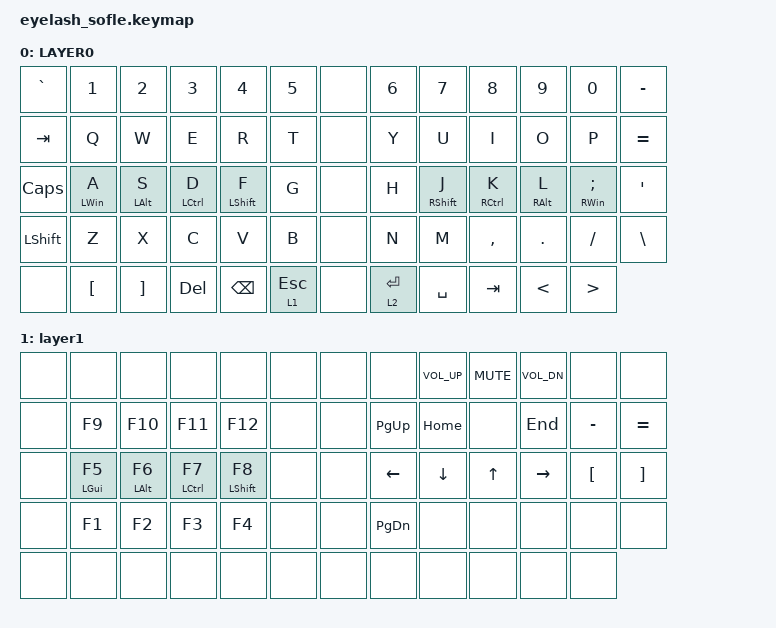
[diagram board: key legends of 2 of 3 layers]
#include <behaviors.dtsi>
#include <dt-bindings/zmk/keys.h>

/ {
    combos { compatible = "zmk,combos"; };

    keymap {
        compatible = "zmk,keymap";

        Base {
            bindings = <
&kp GRAVE  &kp N1            &kp N2             &kp N3       &kp N4         &kp N5       &none  &kp N6       &kp N7             &kp N8       &kp N9           &kp N0            &kp MINUS
&kp TAB    &kp Q             &kp W              &kp E        &kp R          &kp T        &none  &kp Y        &kp U              &kp I        &kp O            &kp P             &kp EQUAL
&kp CAPS   &mt LWIN A        &mt LEFT_ALT S     &mt LCTRL D  &mt LSHIFT F   &kp G        &none  &kp H        &mt RIGHT_SHIFT J  &mt RCTRL K  &mt RIGHT_ALT L  &mt RWIN SEMI     &kp APOS
&kp LSHFT  &kp Z             &kp X              &kp C        &kp V          &kp B        &none  &kp N        &kp M              &kp COMMA    &kp DOT          &kp FSLH          &kp BACKSLASH
&none      &kp LEFT_BRACKET  &kp RIGHT_BRACKET  &kp DEL      &kp BACKSPACE  &lt 1 ESC    &none  &lt 2 ENTER  &kp SPACE          &kp TAB      &kp LESS_THAN    &kp GREATER_THAN
            >;

            display-name = "LAYER0";
        };

        Funcs-Cursor {
            bindings = <
&none  &none            &none            &none                &none              &none    &none  &none           &kp C_VOL_UP    &kp K_MUTE    &kp C_VOL_DN  &none             &none
&none  &kp F9           &kp F10          &kp F11              &kp F12            &none    &none  &kp PG_UP       &kp HOME        &none         &kp END       &kp MINUS         &kp EQUAL
&none  &mt LEFT_GUI F5  &mt LEFT_ALT F6  &mt LEFT_CONTROL F7  &mt LEFT_SHIFT F8  &none    &none  &kp LEFT_ARROW  &kp DOWN_ARROW  &kp UP_ARROW  &kp RIGHT     &kp LEFT_BRACKET  &kp RIGHT_BRACKET
&none  &kp F1           &kp F2           &kp F3               &kp F4             &none    &none  &kp PAGE_DOWN   &none           &none         &none         &none             &none
&none  &none            &none            &none                &none              &none    &none  &none           &none           &none         &none         &none
            >;

            display-name = "layer1";
        };

        Prog-Nums {
            bindings = <
&kp LS(TILDE)  &kp LBKT       &kp LS(LPAR)  &kp LS(RPAR)   &kp RBKT      &kp LS(QMARK)    &none  &none  &none            &none              &none          &none     &none
&kp FSLH       &kp LS(LBRC)   &kp GRAVE     &kp SQT        &kp LS(RBRC)  &kp LS(AT)       &none  &none  &none            &none              &none          &none     &none
&kp LS(POUND)  &kp LS(CARET)  &kp LS(DQT)   &kp LS(UNDER)  &kp LS(DLLR)  &kp LS(PRCNT)    &none  &none  &kp RIGHT_SHIFT  &kp RIGHT_CONTROL  &kp RIGHT_ALT  &kp RGUI  &none
&kp LS(EXCL)   &kp LS(LT)     &kp MINUS     &kp EQUAL      &kp LS(GT)    &kp LS(PLUS)     &none  &none  &none            &none              &none          &none     &none
&none          &kp LS(AMPS)   &kp LS(PIPE)  &kp BSLH       &none         &none            &none  &none  &none            &none              &none
            >;

            display-name = "layer2";
        };
    };
};

/* Mod-tap: longer tapping term = less sensitive (more time to release for tap) */

&mt {
    tapping-term-ms = <250>;
    flavor = "tap-preferred";
};
